# MKL03Z4 register map
Vendor: Freescale Semiconductor, Inc.; Series: Kinetis_L; File version: 1.6
CPU: CM0PLUS r0p0, little endian, no MPU, no FPU, VTOR, 2 interrupt priority bits
Registers are 32-bit, read-write, reset 0x0 unless marked. A register's access mark holds for its fields unless they carry their own. Offsets are from the block's base; [hi:lo] are bit positions; {n}, {i} and the like mark numbered series; 'fields as' and 'values as' point back to an identical list.

## VREF — Voltage Reference
Base 0x40074000; register names take the prefix VREF_
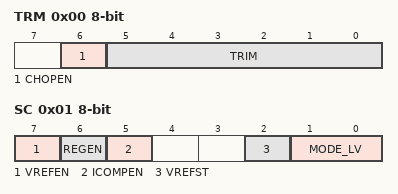
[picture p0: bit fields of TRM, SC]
0x00 TRM 8-bit (reset mask 0x40) — VREF Trim Register
  [6] CHOPEN — Chop oscillator enable. When set, internal chopping operation is enabled and the internal analog offset will be minimized.
    0=Chop oscillator is disabled; 1=Chop oscillator is enabled
  [5:0] TRIM — Trim bits
    0=Min; 63=Max
0x01 SC 8-bit — VREF Status and Control Register
  [7] VREFEN — Internal Voltage Reference enable
    0=The module is disabled; 1=The module is enabled
  [6] REGEN — Regulator enable
    0=Internal 1.75 V regulator is disabled; 1=Internal 1.75 V regulator is enabled
  [5] ICOMPEN — Second order curvature compensation enable
    0=Disabled; 1=Enabled
  [2] VREFST ro — Internal Voltage Reference stable
    0=The module is disabled or not stable; 1=The module is stable
  [1:0] MODE_LV — Buffer Mode selection
    0=Bandgap on only, for stabilization and startup; 1=High power buffer mode enabled; 2=Low-power buffer mode enabled

## LLWU — Low leakage wakeup unit
Base 0x4007C000; register names take the prefix LLWU_
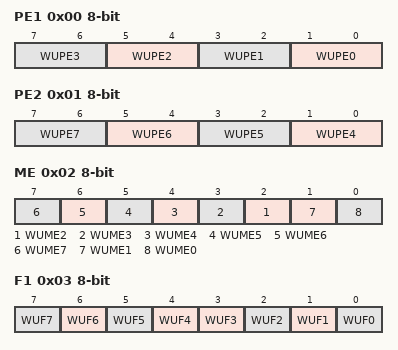
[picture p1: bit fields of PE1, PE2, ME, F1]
0x00 PE1 8-bit — LLWU Pin Enable 1 register
  [all] fields
    0=External input pin disabled as wakeup input; 1=External input pin enabled with rising edge detection; 2=External input pin enabled with falling edge detection; 3=External input pin enabled with any change detection
  [2n+1:2n] WUPE{n} (n=0..3) — Wakeup Pin Enable For LLWU_P{n}
0x01 PE2 8-bit — LLWU Pin Enable 2 register
  [all] fields
    values as the fields of PE1
  [2n-7:2n-8] WUPE{n} (n=4..7) — Wakeup Pin Enable For LLWU_P{n}
0x02 ME 8-bit — LLWU Module Enable register
  [all] fields
    0=Internal module flag not used as wakeup source; 1=Internal module flag used as wakeup source
  [n] WUME{n} (n=2..7) — Wakeup Module Enable For Module {n}
  [1] WUME1 — Wakeup Module Enable for Module 1
  [0] WUME0 — Wakeup Module Enable For Module 0
0x03 F1 8-bit — LLWU Flag 1 register
  [n] WUF{n} (n=4..7) — Wakeup Flag For LLWU_P{n}
    0=LLWU_P{n} input was not a wakeup source; 1=LLWU_P{n} input was a wakeup source
  [3] WUF3 — Wakeup Flag For LLWU_P3
    0=LLWU_P3 input was not a wake-up source; 1=LLWU_P3 input was a wake-up source
  [2] WUF2 — Wakeup Flag For LLWU_P2
    0=LLWU_P2 input was not a wakeup source; 1=LLWU_P2 input was a wakeup source
  [1] WUF1 — Wakeup Flag For LLWU_P1
    0=LLWU_P1 input was not a wakeup source; 1=LLWU_P1 input was a wakeup source
  [0] WUF0 — Wakeup Flag For LLWU_P0
    0=LLWU_P0 input was not a wakeup source; 1=LLWU_P0 input was a wakeup source
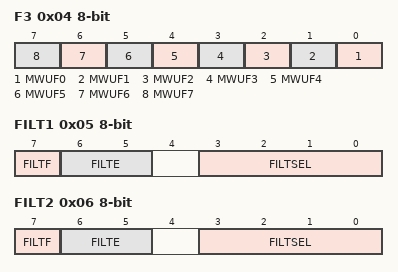
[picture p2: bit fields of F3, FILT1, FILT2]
0x04 F3 8-bit ro — LLWU Flag 3 register
  [n] MWUF{n} (n=0..7) — Wakeup flag For module {n}
    0=Module {n} input was not a wakeup source; 1=Module {n} input was a wakeup source
0x05 FILT1 8-bit — LLWU Pin Filter 1 register
  [7] FILTF — Filter Detect Flag
    0=Pin Filter 1 was not a wakeup source; 1=Pin Filter 1 was a wakeup source
  [6:5] FILTE — Digital Filter On External Pin
    0=Filter disabled; 1=Filter posedge detect enabled; 2=Filter negedge detect enabled; 3=Filter any edge detect enabled
  [3:0] FILTSEL — Filter Pin Select
    0=Select LLWU_P0 for filter; 15=Select LLWU_P15 for filter
0x06 FILT2 8-bit — LLWU Pin Filter 2 register
  [7] FILTF — Filter Detect Flag
    0=Pin Filter 2 was not a wakeup source; 1=Pin Filter 2 was a wakeup source
  [6:5] FILTE — Digital Filter On External Pin
    values as FILT1.FILTE
  [3:0] FILTSEL — Filter Pin Select
    0=Select LLWU_P0 for filter; 15=Select LLWU_P15 for filter

## PMC — Power Management Controller
Base 0x4007D000; register names take the prefix PMC_
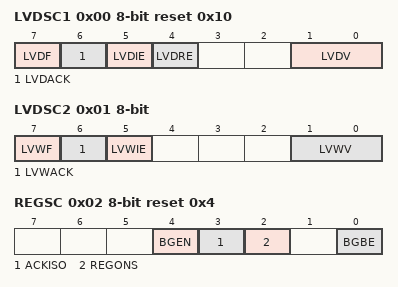
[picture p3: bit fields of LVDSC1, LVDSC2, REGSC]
0x00 LVDSC1 8-bit reset 0x10 — Low Voltage Detect Status And Control 1 register
  [7] LVDF ro — Low-Voltage Detect Flag
    0=Low-voltage event not detected; 1=Low-voltage event detected
  [6] LVDACK wo — Low-Voltage Detect Acknowledge
  [5] LVDIE — Low-Voltage Detect Interrupt Enable
    0=Hardware interrupt disabled (use polling); 1=Request a hardware interrupt when LVDF = 1
  [4] LVDRE — Low-Voltage Detect Reset Enable
    0=LVDF does not generate hardware resets; 1=Force an MCU reset when LVDF = 1
  [1:0] LVDV — Low-Voltage Detect Voltage Select
    0=Low trip point selected (V LVD = V LVDL ); 1=High trip point selected (V LVD = V LVDH )
0x01 LVDSC2 8-bit — Low Voltage Detect Status And Control 2 register
  [7] LVWF ro — Low-Voltage Warning Flag
    0=Low-voltage warning event not detected; 1=Low-voltage warning event detected
  [6] LVWACK wo — Low-Voltage Warning Acknowledge
  [5] LVWIE — Low-Voltage Warning Interrupt Enable
    0=Hardware interrupt disabled (use polling); 1=Request a hardware interrupt when LVWF = 1
  [1:0] LVWV — Low-Voltage Warning Voltage Select
    0=Low trip point selected (VLVW = VLVW1); 1=Mid 1 trip point selected (VLVW = VLVW2); 2=Mid 2 trip point selected (VLVW = VLVW3); 3=High trip point selected (VLVW = VLVW4)
0x02 REGSC 8-bit reset 0x4 — Regulator Status And Control register
  [4] BGEN — Bandgap Enable In VLPx Operation
    0=Bandgap voltage reference is disabled in VLPx , and VLLSx modes; 1=Bandgap voltage reference is enabled in VLPx , and VLLSx modes
  [3] ACKISO — Acknowledge Isolation
    0=Peripherals and I/O pads are in normal run state; 1=Certain peripherals and I/O pads are in an isolated and latched state
  [2] REGONS ro — Regulator In Run Regulation Status
    0=Regulator is in stop regulation or in transition to/from it; 1=Regulator is in run regulation
  [0] BGBE — Bandgap Buffer Enable
    0=Bandgap buffer not enabled; 1=Bandgap buffer enabled
